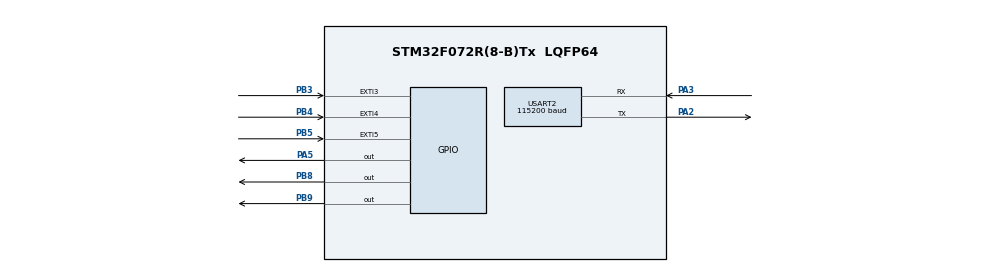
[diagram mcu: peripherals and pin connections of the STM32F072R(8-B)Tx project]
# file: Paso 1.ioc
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Mcu.Family=STM32F0
Mcu.Name=STM32F072R(8-B)Tx
Mcu.Package=LQFP64
NVIC.EXTI2_3_IRQn=true\:0\:0\:false\:false\:true\:true\:true
NVIC.EXTI4_15_IRQn=true\:0\:0\:false\:false\:true\:true\:true
PA13.Mode=Serial_Wire
PA13.Signal=SYS_SWDIO
PA14.Mode=Serial_Wire
PA14.Signal=SYS_SWCLK
PA2.Mode=Asynchronous
PA2.Signal=USART2_TX
PA3.Mode=Asynchronous
PA3.Signal=USART2_RX
PA5.Signal=GPIO_Output
PB3.Signal=GPXTI3
PB4.Signal=GPXTI4
PB5.Signal=GPXTI5
PB8.Signal=GPIO_Output
PB9.Signal=GPIO_Output
ProjectManager.HeapSize=0x200
ProjectManager.StackSize=0x400
ProjectManager.TargetToolchain=TrueSTUDIO
USART2.BaudRate=115200
USART2.VirtualMode-Asynchronous=VM_ASYNC
board=custom

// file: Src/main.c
/* USER CODE BEGIN Header */
/**
 ******************************************************************************
 * @file           : main.c
 * @brief          : Main program body
 ******************************************************************************
 * @attention
 *
 * <h2><center>&copy; Copyright (c) 2019 STMicroelectronics.
 * All rights reserved.</center></h2>
 *
 * This software component is licensed by ST under BSD 3-Clause license,
 * the "License"; You may not use this file except in compliance with the
 * License. You may obtain a copy of the License at:
 *                        opensource.org/licenses/BSD-3-Clause
 *
 ******************************************************************************
 */
/* USER CODE END Header */

#include "main.h"

/* USER CODE BEGIN Includes */
#include <stdlib.h>
#include "simon.h"
/* USER CODE END Includes */

UART_HandleTypeDef huart2;

void SystemClock_Config(void);
static void MX_GPIO_Init(void);
static void MX_USART2_UART_Init(void);

/* USER CODE BEGIN 0 */
static void (*_IRQ_BTN_handler)(uint16_t);
/* USER CODE END 0 */

int main(void)
{

  /* MCU Configuration--------------------------------------------------------*/

  /* Reset of all peripherals, Initializes the Flash interface and the Systick. */
  HAL_Init();

  /* Configure the system clock */
  SystemClock_Config();

  /* Initialize all configured peripherals */
  MX_GPIO_Init();
  MX_USART2_UART_Init();
  /* USER CODE BEGIN 2 */
	//LED Test
	simon_t* simon = simon_init(HAL_GetTick());
	_IRQ_BTN_handler = simon->_IRQ_BTN_handler;

  /* USER CODE END 2 */

  /* Infinite loop */
	while (1) {

	}
}

void SystemClock_Config(void)
{
  RCC_OscInitTypeDef RCC_OscInitStruct = {0};
  RCC_ClkInitTypeDef RCC_ClkInitStruct = {0};
  RCC_PeriphCLKInitTypeDef PeriphClkInit = {0};

  /** Initializes the CPU, AHB and APB busses clocks
  */
  RCC_OscInitStruct.OscillatorType = RCC_OSCILLATORTYPE_HSI;
  RCC_OscInitStruct.HSIState = RCC_HSI_ON;
  RCC_OscInitStruct.HSICalibrationValue = RCC_HSICALIBRATION_DEFAULT;
  RCC_OscInitStruct.PLL.PLLState = RCC_PLL_NONE;
  if (HAL_RCC_OscConfig(&RCC_OscInitStruct) != HAL_OK)
  {
    Error_Handler();
  }
  /** Initializes the CPU, AHB and APB busses clocks
  */
  RCC_ClkInitStruct.ClockType = RCC_CLOCKTYPE_HCLK|RCC_CLOCKTYPE_SYSCLK
                              |RCC_CLOCKTYPE_PCLK1;
  RCC_ClkInitStruct.SYSCLKSource = RCC_SYSCLKSOURCE_HSI;
  RCC_ClkInitStruct.AHBCLKDivider = RCC_SYSCLK_DIV1;
  RCC_ClkInitStruct.APB1CLKDivider = RCC_HCLK_DIV1;

  if (HAL_RCC_ClockConfig(&RCC_ClkInitStruct, FLASH_LATENCY_0) != HAL_OK)
  {
    Error_Handler();
  }
  PeriphClkInit.PeriphClockSelection = RCC_PERIPHCLK_USART2;
  PeriphClkInit.Usart2ClockSelection = RCC_USART2CLKSOURCE_PCLK1;
  if (HAL_RCCEx_PeriphCLKConfig(&PeriphClkInit) != HAL_OK)
  {
    Error_Handler();
  }
}

static void MX_USART2_UART_Init(void)
{

  huart2.Instance = USART2;
  huart2.Init.BaudRate = 115200;
  huart2.Init.WordLength = UART_WORDLENGTH_8B;
  huart2.Init.StopBits = UART_STOPBITS_1;
  huart2.Init.Parity = UART_PARITY_NONE;
  huart2.Init.Mode = UART_MODE_TX_RX;
  huart2.Init.HwFlowCtl = UART_HWCONTROL_NONE;
  huart2.Init.OverSampling = UART_OVERSAMPLING_16;
  huart2.Init.OneBitSampling = UART_ONE_BIT_SAMPLE_DISABLE;
  huart2.AdvancedInit.AdvFeatureInit = UART_ADVFEATURE_NO_INIT;
  if (HAL_UART_Init(&huart2) != HAL_OK)
  {
    Error_Handler();
  }

}

static void MX_GPIO_Init(void)
{
  GPIO_InitTypeDef GPIO_InitStruct = {0};

  /* GPIO Ports Clock Enable */
  __HAL_RCC_GPIOA_CLK_ENABLE();
  __HAL_RCC_GPIOB_CLK_ENABLE();

  /*Configure GPIO pin Output Level */
  HAL_GPIO_WritePin(GPIOA, GPIO_PIN_5, GPIO_PIN_RESET);

  /*Configure GPIO pin Output Level */
  HAL_GPIO_WritePin(GPIOB, GPIO_PIN_8|GPIO_PIN_9, GPIO_PIN_RESET);

  /*Configure GPIO pin : PA5 */
  GPIO_InitStruct.Pin = GPIO_PIN_5;
  GPIO_InitStruct.Mode = GPIO_MODE_OUTPUT_PP;
  GPIO_InitStruct.Pull = GPIO_NOPULL;
  GPIO_InitStruct.Speed = GPIO_SPEED_FREQ_LOW;
  HAL_GPIO_Init(GPIOA, &GPIO_InitStruct);

  /*Configure GPIO pins : PB3 PB4 PB5 */
  GPIO_InitStruct.Pin = GPIO_PIN_3|GPIO_PIN_4|GPIO_PIN_5;
  GPIO_InitStruct.Mode = GPIO_MODE_IT_RISING;
  GPIO_InitStruct.Pull = GPIO_NOPULL;
  HAL_GPIO_Init(GPIOB, &GPIO_InitStruct);

  /*Configure GPIO pins : PB8 PB9 */
  GPIO_InitStruct.Pin = GPIO_PIN_8|GPIO_PIN_9;
  GPIO_InitStruct.Mode = GPIO_MODE_OUTPUT_PP;
  GPIO_InitStruct.Pull = GPIO_NOPULL;
  GPIO_InitStruct.Speed = GPIO_SPEED_FREQ_LOW;
  HAL_GPIO_Init(GPIOB, &GPIO_InitStruct);

  /* EXTI interrupt init*/
  HAL_NVIC_SetPriority(EXTI2_3_IRQn, 0, 0);
  HAL_NVIC_EnableIRQ(EXTI2_3_IRQn);

  HAL_NVIC_SetPriority(EXTI4_15_IRQn, 0, 0);
  HAL_NVIC_EnableIRQ(EXTI4_15_IRQn);

}

/* USER CODE BEGIN 4 */
void HAL_GPIO_EXTI_Callback(uint16_t GPIO_Pin) {
	_IRQ_BTN_handler(GPIO_Pin);
}
/* USER CODE END 4 */

void Error_Handler(void)
{
}

/************************ (C) COPYRIGHT STMicroelectronics *****END OF FILE****/
